# AVRSTYLE8 register map
Vendor: ETK-Test; File version: 1.0
AVR 风格测试芯片：数据空间地址口径 0x800000+偏移、I/O 空间访问宏（_SFR_IO8）、isDefault 枚举
CPU: other r0p0, little endian, no MPU, no FPU, 0 interrupt priority bits
Registers are 8-bit, read-write, reset 0x0 unless marked. A register's access mark holds for its fields unless they carry their own. Offsets are from the block's base; lines under a group give offsets from that group; [hi:lo] are bit positions; {n}, {i} and the like mark numbered series; 'fields as' and 'values as' point back to an identical list; <NAME> marks a mode.

## Memory map
0x00800000 PORTB size 0x100

## PORTB
Base 0x00800000
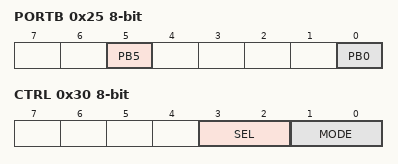
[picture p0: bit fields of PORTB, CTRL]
0x25 PORTB — Port B data register
  [5] PB5 — Port B bit 5
  [0] PB0 — Port B bit 0
0x30 CTRL — Control register
  [3:2] SEL — Select (with default)
    0=A; 1=B; other=OTHER
  [1:0] MODE — Mode select (no default)
    0=OFF; 1=ON
0x31 STAT read-has-side-effects — Status register (read may be modified by hardware)
